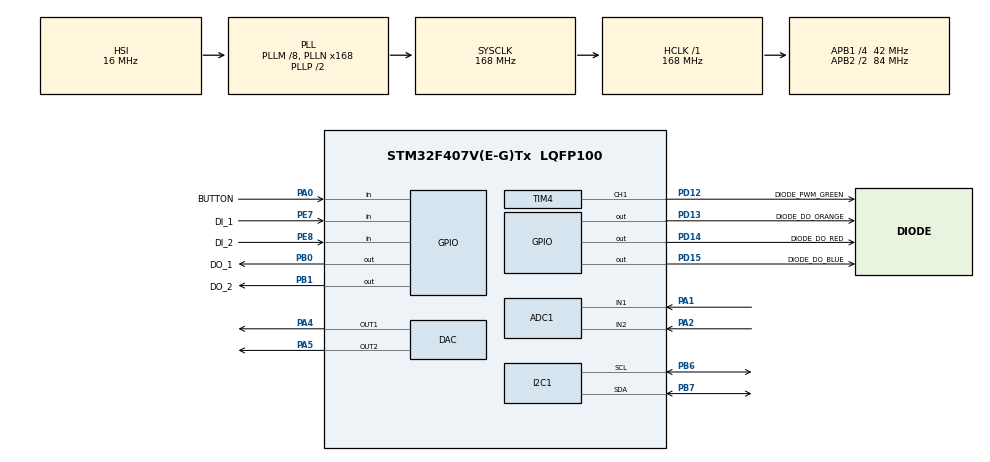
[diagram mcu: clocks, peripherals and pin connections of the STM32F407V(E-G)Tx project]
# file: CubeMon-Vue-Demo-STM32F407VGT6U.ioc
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ADC1.Channel-0\#ChannelRegularConversion=ADC_CHANNEL_1
ADC1.Channel-1\#ChannelRegularConversion=ADC_CHANNEL_1
ADC1.Channel-2\#ChannelRegularConversion=ADC_CHANNEL_TEMPSENSOR
ADC1.DMAContinuousRequests=ENABLE
ADC1.NbrOfConversion=3
ADC1.NbrOfConversionFlag=1
ADC1.Rank-0\#ChannelRegularConversion=1
ADC1.Rank-1\#ChannelRegularConversion=2
ADC1.Rank-2\#ChannelRegularConversion=3
ADC1.SamplingTime-0\#ChannelRegularConversion=ADC_SAMPLETIME_480CYCLES
ADC1.SamplingTime-1\#ChannelRegularConversion=ADC_SAMPLETIME_480CYCLES
ADC1.SamplingTime-2\#ChannelRegularConversion=ADC_SAMPLETIME_480CYCLES
ADC1.ScanConvMode=ENABLE
ADC1.master=1
Dma.ADC1.0.Direction=DMA_PERIPH_TO_MEMORY
Dma.ADC1.0.FIFOMode=DMA_FIFOMODE_DISABLE
Dma.ADC1.0.Instance=DMA2_Stream0
Dma.ADC1.0.MemDataAlignment=DMA_MDATAALIGN_WORD
Dma.ADC1.0.MemInc=DMA_MINC_ENABLE
Dma.ADC1.0.Mode=DMA_CIRCULAR
Dma.ADC1.0.PeriphDataAlignment=DMA_PDATAALIGN_WORD
Dma.ADC1.0.PeriphInc=DMA_PINC_DISABLE
Dma.ADC1.0.Priority=DMA_PRIORITY_LOW
Dma.Request0=ADC1
Mcu.Family=STM32F4
Mcu.Name=STM32F407V(E-G)Tx
Mcu.Package=LQFP100
NVIC.ADC_IRQn=true\:0\:0\:false\:false\:true\:true\:true
NVIC.DMA2_Stream0_IRQn=true\:0\:0\:false\:false\:true\:false\:true
NVIC.PriorityGroup=NVIC_PRIORITYGROUP_4
NVIC.TIM1_UP_TIM10_IRQn=true\:0\:0\:false\:false\:true\:true\:true
NVIC.TIM8_TRG_COM_TIM14_IRQn=true\:0\:0\:false\:false\:true\:true\:true
NVIC.TIM8_UP_TIM13_IRQn=true\:0\:0\:false\:false\:true\:true\:true
PA0-WKUP.GPIO_Label=BUTTON
PA0-WKUP.GPIO_PuPd=GPIO_PULLDOWN
PA0-WKUP.Signal=GPIO_Input
PA1.Signal=ADCx_IN1
PA13.Mode=Trace_Asynchronous_SW
PA13.Signal=SYS_JTMS-SWDIO
PA14.Mode=Trace_Asynchronous_SW
PA14.Signal=SYS_JTCK-SWCLK
PA2.Signal=ADCx_IN2
PA4.Signal=COMP_DAC1_group
PA5.Signal=COMP_DAC2_group
PB0.GPIO_Label=DO_1
PB0.Signal=GPIO_Output
PB1.GPIO_Label=DO_2
PB1.Signal=GPIO_Output
PB3.Mode=Trace_Asynchronous_SW
PB3.Signal=SYS_JTDO-SWO
PB6.Mode=I2C
PB6.Signal=I2C1_SCL
PB7.Mode=I2C
PB7.Signal=I2C1_SDA
PD12.GPIO_Label=DIODE_PWM_GREEN
PD12.Signal=S_TIM4_CH1
PD13.GPIO_Label=DIODE_DO_ORANGE
PD13.Signal=GPIO_Output
PD14.GPIO_Label=DIODE_DO_RED
PD14.Signal=GPIO_Output
PD15.GPIO_Label=DIODE_DO_BLUE
PD15.Signal=GPIO_Output
PE7.GPIO_Label=DI_1
PE7.GPIO_PuPd=GPIO_PULLUP
PE7.Signal=GPIO_Input
PE8.GPIO_Label=DI_2
PE8.GPIO_PuPd=GPIO_PULLUP
PE8.Signal=GPIO_Input
ProjectManager.HeapSize=0x200
ProjectManager.StackSize=0x400
ProjectManager.TargetToolchain=STM32CubeIDE
RCC.48MHZClocksFreq_Value=84000000
RCC.AHBFreq_Value=168000000
RCC.APB1CLKDivider=RCC_HCLK_DIV4
RCC.APB1Freq_Value=42000000
RCC.APB1TimFreq_Value=84000000
RCC.APB2CLKDivider=RCC_HCLK_DIV2
RCC.APB2Freq_Value=84000000
RCC.APB2TimFreq_Value=168000000
RCC.CortexFreq_Value=168000000
RCC.HCLKFreq_Value=168000000
RCC.HSE_VALUE=25000000
RCC.HSI_VALUE=16000000
RCC.LSE_VALUE=32768
RCC.PLLM=8
RCC.PLLN=168
RCC.SYSCLKFreq_VALUE=168000000
RCC.SYSCLKSource=RCC_SYSCLKSOURCE_PLLCLK
RCC.VCOOutputFreq_Value=336000000
SH.ADCx_IN1.0=ADC1_IN1,IN1
SH.ADCx_IN2.0=ADC1_IN2,IN2
SH.COMP_DAC1_group.0=DAC_OUT1,DAC_OUT1
SH.COMP_DAC2_group.0=DAC_OUT2,DAC_OUT2
SH.S_TIM4_CH1.0=TIM4_CH1,PWM Generation1 CH1
TIM10.Period=55999
TIM10.Prescaler=2
TIM13.Period=63999
TIM13.Prescaler=2624
TIM14.Period=62999
TIM14.Prescaler=79
TIM4.Channel-PWM\ Generation1\ CH1=TIM_CHANNEL_1
TIM4.Period=256
TIM4.Prescaler=3
VP_ADC1_TempSens_Input.Mode=IN-TempSens
VP_IWDG_VS_IWDG.Mode=IWDG_Activate
VP_TIM10_VS_ClockSourceINT.Mode=Enable_Timer
VP_TIM13_VS_ClockSourceINT.Mode=Enable_Timer
VP_TIM14_VS_ClockSourceINT.Mode=Enable_Timer
board=custom

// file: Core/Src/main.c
/* USER CODE BEGIN Header */
/**
 ******************************************************************************
 * @file           : main.c
 * @brief          : Main program body
 ******************************************************************************
 * @attention
 *
 * Copyright (c) 2022 STMicroelectronics.
 * All rights reserved.
 *
 * This software is licensed under terms that can be found in the LICENSE file
 * in the root directory of this software component.
 * If no LICENSE file comes with this software, it is provided AS-IS.
 *
 ******************************************************************************
 */
/* USER CODE END Header */
#include "main.h"
#include <prog/init.h>

ADC_HandleTypeDef hadc1;
DMA_HandleTypeDef hdma_adc1;

DAC_HandleTypeDef hdac;

I2C_HandleTypeDef hi2c1;

IWDG_HandleTypeDef hiwdg;

TIM_HandleTypeDef htim4;
TIM_HandleTypeDef htim10;
TIM_HandleTypeDef htim13;
TIM_HandleTypeDef htim14;

void SystemClock_Config(void);
static void MX_GPIO_Init(void);
static void MX_DMA_Init(void);
static void MX_ADC1_Init(void);
static void MX_DAC_Init(void);
static void MX_I2C1_Init(void);
static void MX_TIM4_Init(void);
static void MX_TIM10_Init(void);
static void MX_TIM13_Init(void);
static void MX_TIM14_Init(void);
#ifdef USE_WATCHDOG
static void MX_IWDG_Init(void);
#endif

int main(void) {

	/* MCU Configuration--------------------------------------------------------*/

	/* Reset of all peripherals, Initializes the Flash interface and the Systick. */
	HAL_Init();

	/* Configure the system clock */
	SystemClock_Config();

	/* Initialize all configured peripherals */
	MX_GPIO_Init();
	MX_DMA_Init();
	MX_ADC1_Init();
	MX_DAC_Init();
	MX_I2C1_Init();
	MX_TIM4_Init();
	MX_TIM10_Init();
	MX_TIM13_Init();
	MX_TIM14_Init();
#ifdef USE_WATCHDOG
	 MX_IWDG_Init();
#endif
	/* USER CODE BEGIN 2 */

	init();
	HAL_TIM_Base_Start_IT(&htim10);
	HAL_TIM_Base_Start_IT(&htim13);
	HAL_TIM_Base_Start_IT(&htim14);
	/* USER CODE END 2 */

	/* Infinite loop */
	/* USER CODE BEGIN WHILE */
	while (1) {
#ifdef USE_WATCHDOG
		HAL_IWDG_Refresh(&hiwdg);
#endif
		/* USER CODE END WHILE */

	}
}

void SystemClock_Config(void) {
	RCC_OscInitTypeDef RCC_OscInitStruct = { 0 };
	RCC_ClkInitTypeDef RCC_ClkInitStruct = { 0 };

	/** Configure the main internal regulator output voltage
	 */
	__HAL_RCC_PWR_CLK_ENABLE();
	__HAL_PWR_VOLTAGESCALING_CONFIG(PWR_REGULATOR_VOLTAGE_SCALE1);
	/** Initializes the RCC Oscillators according to the specified parameters
	 * in the RCC_OscInitTypeDef structure.
	 */
	RCC_OscInitStruct.OscillatorType = RCC_OSCILLATORTYPE_HSI
			| RCC_OSCILLATORTYPE_LSI;
	RCC_OscInitStruct.HSIState = RCC_HSI_ON;
	RCC_OscInitStruct.HSICalibrationValue = RCC_HSICALIBRATION_DEFAULT;
	RCC_OscInitStruct.LSIState = RCC_LSI_ON;
	RCC_OscInitStruct.PLL.PLLState = RCC_PLL_ON;
	RCC_OscInitStruct.PLL.PLLSource = RCC_PLLSOURCE_HSI;
	RCC_OscInitStruct.PLL.PLLM = 8;
	RCC_OscInitStruct.PLL.PLLN = 168;
	RCC_OscInitStruct.PLL.PLLP = RCC_PLLP_DIV2;
	RCC_OscInitStruct.PLL.PLLQ = 4;
	if (HAL_RCC_OscConfig(&RCC_OscInitStruct) != HAL_OK) {
		Error_Handler();
	}
	/** Initializes the CPU, AHB and APB buses clocks
	 */
	RCC_ClkInitStruct.ClockType = RCC_CLOCKTYPE_HCLK | RCC_CLOCKTYPE_SYSCLK
			| RCC_CLOCKTYPE_PCLK1 | RCC_CLOCKTYPE_PCLK2;
	RCC_ClkInitStruct.SYSCLKSource = RCC_SYSCLKSOURCE_PLLCLK;
	RCC_ClkInitStruct.AHBCLKDivider = RCC_SYSCLK_DIV1;
	RCC_ClkInitStruct.APB1CLKDivider = RCC_HCLK_DIV4;
	RCC_ClkInitStruct.APB2CLKDivider = RCC_HCLK_DIV2;

	if (HAL_RCC_ClockConfig(&RCC_ClkInitStruct, FLASH_LATENCY_5) != HAL_OK) {
		Error_Handler();
	}
}

static void MX_ADC1_Init(void) {

	ADC_ChannelConfTypeDef sConfig = { 0 };

	/** Configure the global features of the ADC (Clock, Resolution, Data Alignment and number of conversion)
	 */
	hadc1.Instance = ADC1;
	hadc1.Init.ClockPrescaler = ADC_CLOCK_SYNC_PCLK_DIV8;
	hadc1.Init.Resolution = ADC_RESOLUTION_12B;
	hadc1.Init.ScanConvMode = ENABLE;
	hadc1.Init.ContinuousConvMode = ENABLE;
	hadc1.Init.DiscontinuousConvMode = DISABLE;
	hadc1.Init.ExternalTrigConvEdge = ADC_EXTERNALTRIGCONVEDGE_NONE;
	hadc1.Init.ExternalTrigConv = ADC_SOFTWARE_START;
	hadc1.Init.DataAlign = ADC_DATAALIGN_RIGHT;
	hadc1.Init.NbrOfConversion = 3;
	hadc1.Init.DMAContinuousRequests = ENABLE;
	hadc1.Init.EOCSelection = ADC_EOC_SEQ_CONV;
	if (HAL_ADC_Init(&hadc1) != HAL_OK) {
		Error_Handler();
	}
	/** Configure for the selected ADC regular channel its corresponding rank in the sequencer and its sample time.
	 */
	sConfig.Channel = ADC_CHANNEL_1;
	sConfig.Rank = 1;
	sConfig.SamplingTime = ADC_SAMPLETIME_480CYCLES;
	if (HAL_ADC_ConfigChannel(&hadc1, &sConfig) != HAL_OK) {
		Error_Handler();
	}
	/** Configure for the selected ADC regular channel its corresponding rank in the sequencer and its sample time.
	 */
	sConfig.Channel = ADC_CHANNEL_2;
	sConfig.Rank = 2;
	if (HAL_ADC_ConfigChannel(&hadc1, &sConfig) != HAL_OK) {
		Error_Handler();
	}
	/** Configure for the selected ADC regular channel its corresponding rank in the sequencer and its sample time.
	 */
	sConfig.Channel = ADC_CHANNEL_TEMPSENSOR;
	sConfig.Rank = 3;
	if (HAL_ADC_ConfigChannel(&hadc1, &sConfig) != HAL_OK) {
		Error_Handler();
	}

}

static void MX_DAC_Init(void) {

	DAC_ChannelConfTypeDef sConfig = { 0 };

	/** DAC Initialization
	 */
	hdac.Instance = DAC;
	if (HAL_DAC_Init(&hdac) != HAL_OK) {
		Error_Handler();
	}
	/** DAC channel OUT1 config
	 */
	sConfig.DAC_Trigger = DAC_TRIGGER_NONE;
	sConfig.DAC_OutputBuffer = DAC_OUTPUTBUFFER_ENABLE;
	if (HAL_DAC_ConfigChannel(&hdac, &sConfig, DAC_CHANNEL_1) != HAL_OK) {
		Error_Handler();
	}
	/** DAC channel OUT2 config
	 */
	if (HAL_DAC_ConfigChannel(&hdac, &sConfig, DAC_CHANNEL_2) != HAL_OK) {
		Error_Handler();
	}

}

static void MX_I2C1_Init(void) {

	hi2c1.Instance = I2C1;
	hi2c1.Init.ClockSpeed = 100000;
	hi2c1.Init.DutyCycle = I2C_DUTYCYCLE_2;
	hi2c1.Init.OwnAddress1 = 0;
	hi2c1.Init.AddressingMode = I2C_ADDRESSINGMODE_7BIT;
	hi2c1.Init.DualAddressMode = I2C_DUALADDRESS_DISABLE;
	hi2c1.Init.OwnAddress2 = 0;
	hi2c1.Init.GeneralCallMode = I2C_GENERALCALL_DISABLE;
	hi2c1.Init.NoStretchMode = I2C_NOSTRETCH_DISABLE;
	if (HAL_I2C_Init(&hi2c1) != HAL_OK) {
		Error_Handler();
	}

}

#ifdef USE_WATCHDOG
static void MX_IWDG_Init(void) {

	hiwdg.Instance = IWDG;
	hiwdg.Init.Prescaler = IWDG_PRESCALER_4;
	hiwdg.Init.Reload = 4095;
	if (HAL_IWDG_Init(&hiwdg) != HAL_OK) {
		Error_Handler();
	}

}
#endif
static void MX_TIM4_Init(void) {

	TIM_MasterConfigTypeDef sMasterConfig = { 0 };
	TIM_OC_InitTypeDef sConfigOC = { 0 };

	htim4.Instance = TIM4;
	htim4.Init.Prescaler = 3;
	htim4.Init.CounterMode = TIM_COUNTERMODE_UP;
	htim4.Init.Period = 256;
	htim4.Init.ClockDivision = TIM_CLOCKDIVISION_DIV1;
	htim4.Init.AutoReloadPreload = TIM_AUTORELOAD_PRELOAD_DISABLE;
	if (HAL_TIM_PWM_Init(&htim4) != HAL_OK) {
		Error_Handler();
	}
	sMasterConfig.MasterOutputTrigger = TIM_TRGO_RESET;
	sMasterConfig.MasterSlaveMode = TIM_MASTERSLAVEMODE_DISABLE;
	if (HAL_TIMEx_MasterConfigSynchronization(&htim4, &sMasterConfig)
			!= HAL_OK) {
		Error_Handler();
	}
	sConfigOC.OCMode = TIM_OCMODE_PWM1;
	sConfigOC.Pulse = 0;
	sConfigOC.OCPolarity = TIM_OCPOLARITY_HIGH;
	sConfigOC.OCFastMode = TIM_OCFAST_DISABLE;
	if (HAL_TIM_PWM_ConfigChannel(&htim4, &sConfigOC, TIM_CHANNEL_1)
			!= HAL_OK) {
		Error_Handler();
	}
	HAL_TIM_MspPostInit(&htim4);

}

static void MX_TIM10_Init(void) {

	htim10.Instance = TIM10;
	htim10.Init.Prescaler = 2;
	htim10.Init.CounterMode = TIM_COUNTERMODE_UP;
	htim10.Init.Period = 55999;
	htim10.Init.ClockDivision = TIM_CLOCKDIVISION_DIV1;
	htim10.Init.AutoReloadPreload = TIM_AUTORELOAD_PRELOAD_DISABLE;
	if (HAL_TIM_Base_Init(&htim10) != HAL_OK) {
		Error_Handler();
	}

}

static void MX_TIM13_Init(void) {

	htim13.Instance = TIM13;
	htim13.Init.Prescaler = 2624;
	htim13.Init.CounterMode = TIM_COUNTERMODE_UP;
	htim13.Init.Period = 63999;
	htim13.Init.ClockDivision = TIM_CLOCKDIVISION_DIV1;
	htim13.Init.AutoReloadPreload = TIM_AUTORELOAD_PRELOAD_DISABLE;
	if (HAL_TIM_Base_Init(&htim13) != HAL_OK) {
		Error_Handler();
	}

}

static void MX_TIM14_Init(void) {

	htim14.Instance = TIM14;
	htim14.Init.Prescaler = 79;
	htim14.Init.CounterMode = TIM_COUNTERMODE_UP;
	htim14.Init.Period = 62999;
	htim14.Init.ClockDivision = TIM_CLOCKDIVISION_DIV1;
	htim14.Init.AutoReloadPreload = TIM_AUTORELOAD_PRELOAD_DISABLE;
	if (HAL_TIM_Base_Init(&htim14) != HAL_OK) {
		Error_Handler();
	}

}

static void MX_DMA_Init(void) {

	/* DMA controller clock enable */
	__HAL_RCC_DMA2_CLK_ENABLE();

	/* DMA interrupt init */
	/* DMA2_Stream0_IRQn interrupt configuration */
	HAL_NVIC_SetPriority(DMA2_Stream0_IRQn, 0, 0);
	HAL_NVIC_EnableIRQ(DMA2_Stream0_IRQn);

}

static void MX_GPIO_Init(void) {
	GPIO_InitTypeDef GPIO_InitStruct = { 0 };

	/* GPIO Ports Clock Enable */
	__HAL_RCC_GPIOA_CLK_ENABLE();
	__HAL_RCC_GPIOB_CLK_ENABLE();
	__HAL_RCC_GPIOE_CLK_ENABLE();
	__HAL_RCC_GPIOD_CLK_ENABLE();

	/*Configure GPIO pin Output Level */
	HAL_GPIO_WritePin(GPIOB, DO_1_Pin | DO_2_Pin, GPIO_PIN_RESET);

	/*Configure GPIO pin Output Level */
	HAL_GPIO_WritePin(GPIOD,
	DIODE_DO_ORANGE_Pin | DIODE_DO_RED_Pin | DIODE_DO_BLUE_Pin, GPIO_PIN_RESET);

	/*Configure GPIO pin : BUTTON_Pin */
	GPIO_InitStruct.Pin = BUTTON_Pin;
	GPIO_InitStruct.Mode = GPIO_MODE_INPUT;
	GPIO_InitStruct.Pull = GPIO_PULLDOWN;
	HAL_GPIO_Init(BUTTON_GPIO_Port, &GPIO_InitStruct);

	/*Configure GPIO pins : DO_1_Pin DO_2_Pin */
	GPIO_InitStruct.Pin = DO_1_Pin | DO_2_Pin;
	GPIO_InitStruct.Mode = GPIO_MODE_OUTPUT_PP;
	GPIO_InitStruct.Pull = GPIO_NOPULL;
	GPIO_InitStruct.Speed = GPIO_SPEED_FREQ_LOW;
	HAL_GPIO_Init(GPIOB, &GPIO_InitStruct);

	/*Configure GPIO pins : DI_1_Pin DI_2_Pin */
	GPIO_InitStruct.Pin = DI_1_Pin;
	GPIO_InitStruct.Mode = GPIO_MODE_INPUT;
	GPIO_InitStruct.Pull = GPIO_PULLDOWN;
	HAL_GPIO_Init(GPIOE, &GPIO_InitStruct);

	/*Configure GPIO pins : DI_1_Pin DI_2_Pin */
	GPIO_InitStruct.Pin = DI_2_Pin;
	GPIO_InitStruct.Mode = GPIO_MODE_INPUT;
	GPIO_InitStruct.Pull = GPIO_PULLUP;
	HAL_GPIO_Init(GPIOE, &GPIO_InitStruct);

	/*Configure GPIO pins : DIODE_DO_ORANGE_Pin DIODE_DO_RED_Pin DIODE_DO_BLUE_Pin */
	GPIO_InitStruct.Pin = DIODE_DO_ORANGE_Pin | DIODE_DO_RED_Pin
			| DIODE_DO_BLUE_Pin;
	GPIO_InitStruct.Mode = GPIO_MODE_OUTPUT_PP;
	GPIO_InitStruct.Pull = GPIO_NOPULL;
	GPIO_InitStruct.Speed = GPIO_SPEED_FREQ_LOW;
	HAL_GPIO_Init(GPIOD, &GPIO_InitStruct);

}

void Error_Handler(void) {
	__disable_irq();
	while (1) {
	}
}
